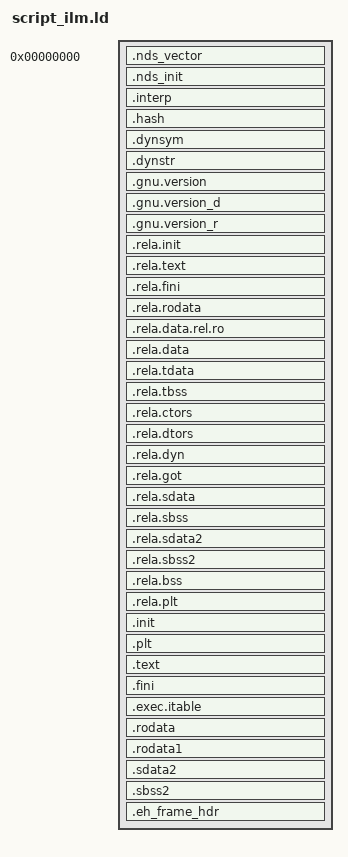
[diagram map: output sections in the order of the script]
/* This file is generated by nds_ldsag (version (2018-07-14) ). */
ENTRY(_start)
SECTIONS
{
    PROVIDE(__TEXT_BASE   = 0x0000000000000000);
    PROVIDE(__LOADER_BASE = 0x0000000000400000);
    PROVIDE (__executable_start = __TEXT_BASE);
    . = __TEXT_BASE;
    
    .nds_vector : { KEEP(*(.nds_vector )) KEEP(*(SORT(.nds_vector.* ))) }
    __boot_start_lma =  LOADADDR (.nds_vector);
    __boot_start = ADDR(.nds_vector);
    .nds_init     : { KEEP(*(.nds_init )) }
    .interp     : { *(.interp ) }    
    .hash     : { *(.hash ) }
    .dynsym     : { *(.dynsym ) }
    .dynstr     : { *(.dynstr ) }    
    .gnu.version     : { *(.gnu.version ) }
    .gnu.version_d     : { *(.gnu.version_d ) }
    .gnu.version_r     : { *(.gnu.version_r ) }
    .rela.init     : { *(.rela.init ) }    
    .rela.text     : { *(.rela.text .rela.text.* .rela.gnu.linkonce.t.* ) }
    .rela.fini     : { *(.rela.fini ) }
    .rela.rodata     : { *(.rela.rodata .rela.rodata.* .rela.gnu.linkonce.r.* ) }    
    .rela.data.rel.ro     : { *(.rel.data.rel.ro* ) }
    .rela.data     : { *(.rela.data .rela.data.* .rela.gnu.linkonce.d.* ) }
    .rela.tdata     : { *(.rela.tdata .rela.tdata.* .rela.gnu.linkonce.td.* ) }
    .rela.tbss     : { *(.rela.tbss .rela.tbss.* .rela.gnu.linkonce.tb.* ) }
    .rela.ctors     : { *(.rela.ctors ) }
    .rela.dtors     : { *(.rela.dtors ) }
    .rela.dyn     : { *(rela.dyn ) *(.rela__libc_subfreeres ) *(.rela__libc_atexit ) *(.rela__libc_thread_subfreeres ) *(.rela.init_array ) *(.rela.fini_array ) }    
    .rela.got     : { *(.rela.got ) }
    .rela.sdata     : { *(.rela.sdata .rela.sdata.* .rela.gnu.linkonce.s.* ) }
    .rela.sbss     : { *(.rela.sbss .rela.sbss.* .rela.gnu.linkonce.sb.* ) }    
    .rela.sdata2     : { *(.rela.sdata2 .rela.sdata2.* .rela.gnu.linkonce.s2.* ) }
    .rela.sbss2     : { *(.rela.sbss2 .rela.sbss2.* .rela.gnu.linkonce.sb2.* ) }
    .rela.bss     : { *(.rela.bss .rela.bss.* .rela.gnu.linkonce.b.* ) }    
    .rela.plt     : { *(.rela.plt ) }
    .init     : { KEEP(*(.init )) }
    .plt     : { *(.plt ) }    
    .text     : { *(.text .stub .text.* .gnu.linkonce.t.* ) KEEP(*(.text.*personality* )) *(.gnu.warning ) . = ALIGN(4); }
    .fini     : { KEEP(*(.fini )) }
    .exec.itable     : { *(.exec.itable ) }    
    PROVIDE (__etext = .);
    PROVIDE (_etext = .);
    PROVIDE (etext = .);
    .rodata     : { *(.rodata .rodata.* .gnu.linkonce.r.* ) }
    .rodata1     : { *(.rodata1 ) }    
    .sdata2     : { *(.sdata2 .sdata2.* .gnu.linkonce.s2.* ) }
    .sbss2     : { *(.sbss2 .sbss2.* .gnu.linkonce.sb2.* ) }
    .eh_frame_hdr     : { *(.eh_frame_hdr ) }
    . = ALIGN(0x20);
    PROVIDE(__DATA_BASE = 0x0000000000100000);
    . = __DATA_BASE;    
